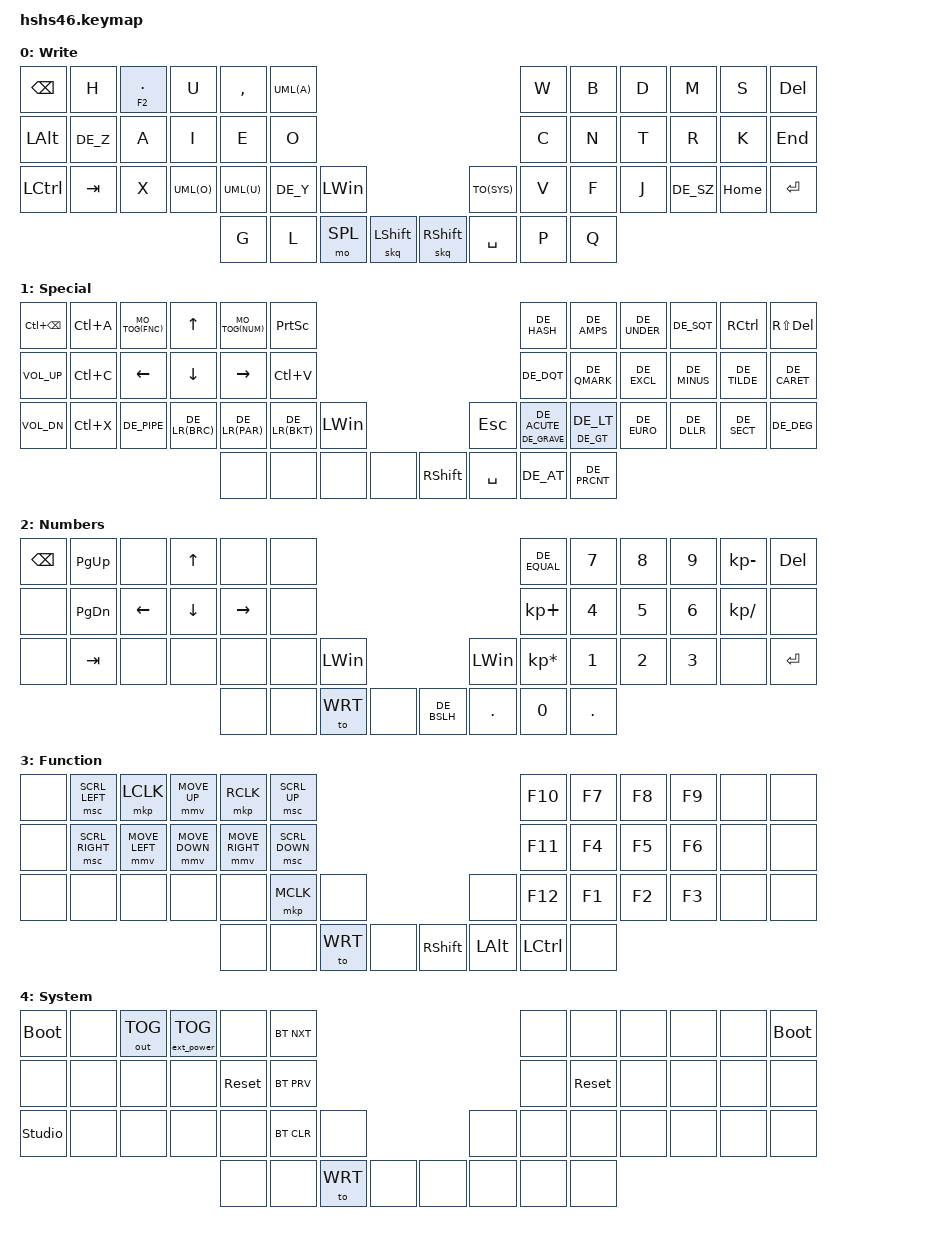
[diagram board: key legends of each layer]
/*
 * Copyright (c) 2021-2022 The ZMK Contributors
 *
 * SPDX-License-Identifier: MIT
 */

#include <behaviors.dtsi>
#include <dt-bindings/zmk/bt.h>
#include <dt-bindings/zmk/ext_power.h>
#include <dt-bindings/zmk/keys.h>
#include <dt-bindings/zmk/outputs.h>
#include <dt-bindings/zmk/pointing.h>
#include <locale/keys_de.h>
#include <dt-bindings/zmk/mouse.h>

#define WRT 0
#define SPL 1
#define NUM 2
#define FNC 3
#define SYS 4

#define MO_TOG(layer) &mo_tog layer layer
#define UML(uml) &kp DE_##uml##_UMLAUT
#define DE_LR(key) &mt DE_R##key DE_L##key
#define GR_AC &mt DE_GRAVE DE_ACUTE
#define LT_GT &mt DE_GT DE_LT
#define TO(layer) &lpls layer 0
#define DOT_F2 &lpkp F2 DOT


/ {
keymap {compatible = "zmk,keymap";

/* WRT

 *  BSP  H .F2 U  ,  Ä                         W  B  D  M  S  DEL
 *  ALT  Z  A  I  E  O                         C  N  T  R  K  END
 *  CTR TAB X  Ö  Ü  Y  WIN               SYS  V  F  J  ß HOM RET
 *                G  L  SPL  SFT     SFT  SPC  P  Q
 */

write_layer {
display-name = "Write";
bindings = <

&kp BSPC &kp H     DOT_F2   &kp U   &kp COMMA  UML(A)                                                         &kp W  &kp B  &kp D  &kp M      &kp S     &kp DEL
&kp LALT &kp DE_Z  &kp A    &kp I   &kp E      &kp O                                                          &kp C  &kp N  &kp T  &kp R      &kp K     &kp END
&kp LCTRL &kp TAB  &kp X    UML(O)  UML(U)     &kp DE_Y  &kp LWIN                                  TO(SYS)    &kp V  &kp F  &kp J  &kp DE_SZ  &kp HOME  &kp RET
                                    &kp G      &kp L     &mo SPL   &skq LSHIFT        &skq RSHIFT  &kp SPACE  &kp P  &kp Q
>;};


/* SPL

 *  CBS CRA FNC CUP NUM PSC                       #   &   _  ' CTR SDL  
 *  VUP CRC CLF CDN CRT CRV                       "   ?   !  -  ~   ^
 *  VDN CRX  |  { } ( ) [ ] WIN              ESC ` ´ < >  €  $  §   °
 *                  --- --- --- ---     SFT  SPC  @   %
 */

special_layer {
display-name = "Special";
bindings = <

&kp LC(BSPC)  &kp LC(A)  MO_TOG(FNC)  &kp UP      MO_TOG(NUM)  &kp PSCRN                                                 &kp DE_HASH  &kp DE_AMPS   &kp DE_UNDER  &kp DE_SQT    &kp RCTRL     &kp RS(DEL) 
&kp C_VOL_UP  &kp LC(C)  &kp LEFT     &kp DOWN    &kp RIGHT    &kp LC(V)                                                 &kp DE_DQT   &kp DE_QMARK  &kp DE_EXCL   &kp DE_MINUS  &kp DE_TILDE  &kp DE_CARET
&kp C_VOL_DN  &kp LC(X)  &kp DE_PIPE  DE_LR(BRC)  DE_LR(PAR)   DE_LR(BKT)  &kp LWIN                           &kp ESC    GR_AC        LT_GT         &kp DE_EURO   &kp DE_DLLR   &kp DE_SECT   &kp DE_DEG
                                                  &none        &none       &none     &none        &kp RSHIFT  &kp SPACE  &kp DE_AT    &kp DE_PRCNT
>;};


/* NUM

 *  BSP PUP --- CUP --- ---                       =  7  8  9  -  DEL
 *  --- PDW CLF CDN CRT ---                       +  4  5  6  /  ---
 *  --- TAB --- --- --- --- WIN             ---   *  1  2  3 --- RET
 *                  --- --- WRT ---      \   .    0  ,
 */

numbers_layer {
display-name = "Numbers";
bindings = <

&kp BSPC  &kp PG_UP  &none     &kp UP    &none      &none                                                        &kp DE_EQUAL     &kp N7      &kp N8  &kp N9  &kp KP_MINUS  &kp DEL 
&none     &kp PG_DN  &kp LEFT  &kp DOWN  &kp RIGHT  &none                                                        &kp KP_PLUS      &kp N4      &kp N5  &kp N6  &kp KP_SLASH  &none
&none     &kp TAB    &none     &none     &none      &none      &kp LWIN                            &kp LEFT_WIN  &kp KP_ASTERISK  &kp N1      &kp N2  &kp N3  &none         &kp RET
                                         &none      &none      &to WRT   &none        &kp DE_BSLH  &kp DOT       &kp N0           &kp DOT
>;};

/* FNC

 *  --- MSL MCL MUP MCR MSU                     F10 FN7 FN8 FN9 --- ---
 *  --- MSR MLF MDN MRT MSD                     F11 FN4 FN5 FN6 --- ---
 *  --- --- --- --- --- MMC ---             --- F12 FN1 FN2 FN3 --- ---
 *                  --- --- WRT ---     SFT ALT CTR ---
 */


function_layer {
display-name = "Function";
bindings = <

&none  &msc SCRL_LEFT   &mkp LCLK       &mmv MOVE_UP    &mkp RCLK        &msc SCRL_UP                                                 &kp F10   &kp F7  &kp F8  &kp F9  &none  &none
&none  &msc SCRL_RIGHT  &mmv MOVE_LEFT  &mmv MOVE_DOWN  &mmv MOVE_RIGHT  &msc SCRL_DOWN                                               &kp F11   &kp F4  &kp F5  &kp F6  &none  &none
&none  &none            &none           &none           &none            &mkp MCLK       &none                             &none      &kp F12   &kp F1  &kp F2  &kp F3  &none  &none
                                                        &none            &none           &to WRT  &none        &kp RSHIFT  &kp LALT   &kp LCTRL  &none
>;};


/* SYS

 * BTL --- BUT EPT --- BNX                     --- --- --- --- --- BTL
 * --- --- --- --- RST BPV                     --- RST --- --- --- ---
 * ULK --- --- --- --- BCL ---             --- --- --- --- --- --- ---
 *                 --- --- WRT ---     --- --- --- ---
 */

system_layer {
display-name = "System";
bindings = <

&bootloader     &none  &out OUT_TOG  &ext_power EP_TOG  &none       &bt BT_NXT                                          &none  &none       &none  &none  &none  &bootloader
&none           &none  &none         &none              &sys_reset  &bt BT_PRV                                          &none  &sys_reset  &none  &none  &none  &none
&studio_unlock  &none  &none         &none              &none       &bt BT_CLR  &none                            &none  &none  &none       &none  &none  &none  &none
                                                        &none       &none       &to WRT  &none            &none  &none  &none  &none
>;};

};

behaviors {
        mo_tog: behavior_mo_tog {
            compatible = "zmk,behavior-hold-tap";
            #binding-cells = <2>;
            flavor = "hold-preferred";
            tapping-term-ms = <160>;
            bindings = <&mo>, <&tog>;
        };

        skq: sticky_key {
            compatible = "zmk,behavior-sticky-key";
            #binding-cells = <1>;
            bindings = <&kp>;
            release-after-ms = <750>;
            quick-release;
            ignore-modifiers;
        };

        mt: mod_tap {
            compatible = "zmk,behavior-hold-tap";
            #binding-cells = <2>;
            flavor = "hold-preferred";
            tapping-term-ms = <160>;
            bindings = <&kp>, <&kp>;
        };

        lpls: long_press_layer_switch {
            compatible = "zmk,behavior-hold-tap";
            #binding-cells = <2>;
            flavor = "hold-preferred";
            tapping-term-ms = <1000>;
            bindings = <&to>, <&none>;
        };

        lpkp: long_press_key {
            compatible = "zmk,behavior-hold-tap";
            #binding-cells = <2>;
            flavor = "tap-preferred";
            tapping-term-ms = <300>;
            bindings = <&kp>, <&kp>;
        };

    };
};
